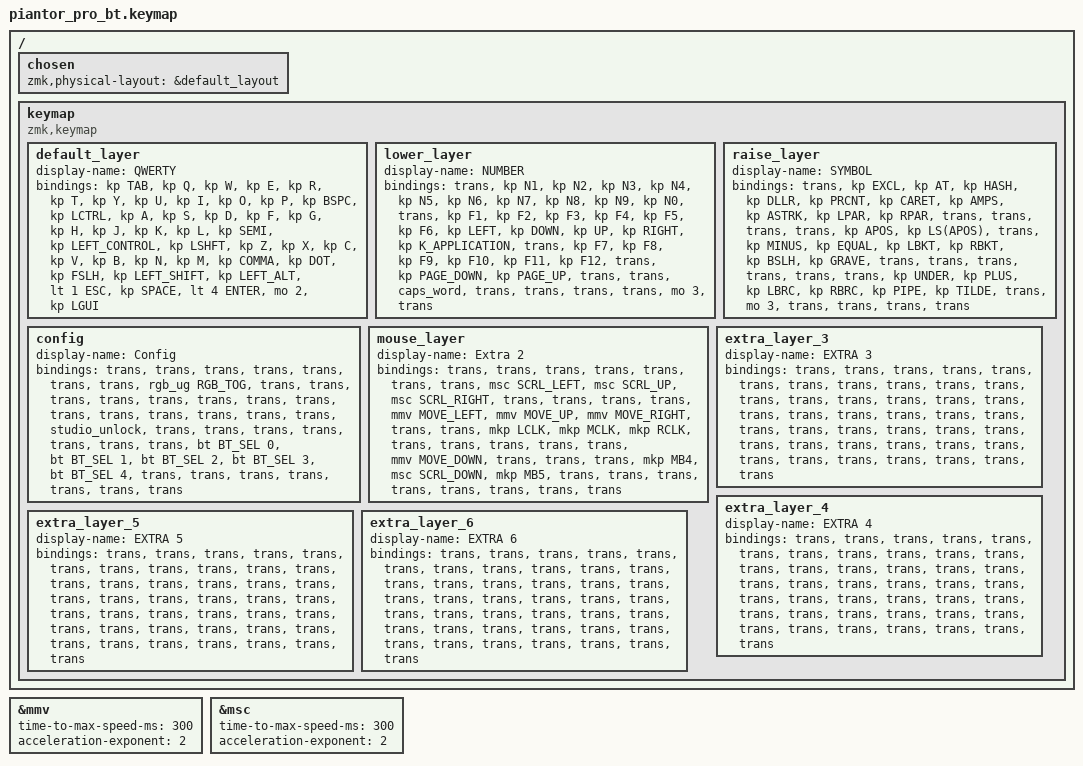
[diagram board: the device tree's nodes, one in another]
/*
 * Copyright (c) 2020 The ZMK Contributors
 *
 * SPDX-License-Identifier: MIT
 */
#define ZMK_POINTING_DEFAULT_MOVE_VAL 1200
#define ZMK_POINTING_DEFAULT_SCRL_VAL 20

#include <behaviors.dtsi>
#include <dt-bindings/zmk/bt.h>
#include <dt-bindings/zmk/keys.h>
#include <dt-bindings/zmk/pointing.h>
#include <dt-bindings/zmk/rgb.h>

&mmv {
    time-to-max-speed-ms = <300>;
    acceleration-exponent = <2>;
};

&msc {
    time-to-max-speed-ms = <300>;
    acceleration-exponent = <2>;
};

/ {
    chosen { zmk,physical-layout = &default_layout; };
};

/ {
    keymap {
        compatible = "zmk,keymap";

        default_layer {
            display-name = "QWERTY";

            // --------------------------------------------------------------------------------
            // |  TAB |  Q  |  W  |  E  |  R  |  T  |  Y  |  U   |  I  |  O  |  P  | BSPC |
            // | CTRL |  A  |  S  |  D  |  F  |  G  |  H  |  J   |  K  |  L  |  ;  |  '   |
            // | SHFT |  Z  |  X  |  C  |  V  |  B  |  N  |  M   |  ,  |  .  |  /  | ESC  |
            //                    | GUI | LWR | SPC | ENT | RSE  | ALT |

            bindings = <
&kp TAB  &kp Q  &kp W  &kp E  &kp R  &kp T  &kp Y  &kp U  &kp I  &kp O  &kp P  &kp BSPC  &kp LCTRL  &kp A  &kp S  &kp D  &kp F  &kp G  &kp H  &kp J  &kp K  &kp L  &kp SEMI  &kp LEFT_CONTROL  &kp LSHFT  &kp Z  &kp X  &kp C  &kp V  &kp B  &kp N  &kp M  &kp COMMA  &kp DOT  &kp FSLH  &kp LEFT_SHIFT  &kp LEFT_ALT  &lt 1 ESC  &kp SPACE  &lt 4 ENTER  &mo 2  &kp LGUI
            >;
        };

        lower_layer {
            display-name = "NUMBER";

            // -----------------------------------------------------------------------------------------
            // |  TAB |  1  |  2  |  3  |  4  |  5    |  6  |  7  |  8  |  9  |  0  | BSPC |
            // | CTRL | BT1 | BT2 | BT3 | BT4 | BT5   | LFT | DWN |  UP | RGT |     |      |
            // | SHFT | BTCR| RGB | RST | BOOT| Unlock|     |     |     |     |     |      |
            //                    | GUI |     | SPC   | ENT |     | ALT |

            bindings = <
&trans  &kp N1  &kp N2  &kp N3  &kp N4  &kp N5  &kp N6  &kp N7  &kp N8  &kp N9  &kp N0  &trans  &kp F1  &kp F2  &kp F3  &kp F4  &kp F5  &kp F6  &kp LEFT  &kp DOWN  &kp UP  &kp RIGHT  &kp K_APPLICATION  &trans  &kp F7  &kp F8  &kp F9  &kp F10  &kp F11  &kp F12  &trans  &kp PAGE_DOWN  &kp PAGE_UP  &trans  &trans  &caps_word  &trans  &trans  &trans  &trans  &mo 3  &trans
            >;
        };

        raise_layer {
            display-name = "SYMBOL";

            // -----------------------------------------------------------------------------------------
            // |  TAB |  !  |  @  |  #  |  $  |  %  |  ^  |  &  |  *  |  (  |  )  | BSPC |
            // | CTRL |     |     |     |     |     |  -  |  =  |  [  |  ]  |  \  |  `   |
            // | SHFT |     |     |     |     |     |  _  |  +  |  {  |  }  | "|" |  ~   |
            //                    | GUI |     | SPC | ENT |     | ALT |

            bindings = <
&trans  &kp EXCL  &kp AT  &kp HASH  &kp DLLR  &kp PRCNT  &kp CARET  &kp AMPS  &kp ASTRK  &kp LPAR  &kp RPAR  &trans  &trans  &trans  &trans  &kp APOS  &kp LS(APOS)  &trans  &kp MINUS  &kp EQUAL  &kp LBKT  &kp RBKT  &kp BSLH  &kp GRAVE  &trans  &trans  &trans  &trans  &trans  &trans  &kp UNDER  &kp PLUS  &kp LBRC  &kp RBRC  &kp PIPE  &kp TILDE  &trans  &mo 3  &trans  &trans  &trans  &trans
            >;
        };

        config {
            display-name = "Config";
            bindings = <
&trans  &trans  &trans  &trans  &trans  &trans  &trans  &rgb_ug RGB_TOG  &trans  &trans  &trans  &trans  &trans  &trans  &trans  &trans  &trans  &trans  &trans  &trans  &trans  &trans  &studio_unlock  &trans  &trans  &trans  &trans  &trans  &trans  &trans  &bt BT_SEL 0  &bt BT_SEL 1  &bt BT_SEL 2  &bt BT_SEL 3  &bt BT_SEL 4  &trans  &trans  &trans  &trans  &trans  &trans  &trans
            >;
        };

        mouse_layer {
            display-name = "Extra 2";
            bindings = <
&trans  &trans  &trans  &trans  &trans  &trans  &trans  &msc SCRL_LEFT  &msc SCRL_UP  &msc SCRL_RIGHT  &trans  &trans  &trans  &trans  &mmv MOVE_LEFT  &mmv MOVE_UP  &mmv MOVE_RIGHT  &trans  &trans  &mkp LCLK  &mkp MCLK  &mkp RCLK  &trans  &trans  &trans  &trans  &trans  &mmv MOVE_DOWN  &trans  &trans  &trans  &mkp MB4  &msc SCRL_DOWN  &mkp MB5  &trans  &trans  &trans  &trans  &trans  &trans  &trans  &trans
            >;
        };

        extra_layer_3 {
            display-name = "EXTRA 3";
            bindings = <
&trans  &trans  &trans  &trans  &trans  &trans  &trans  &trans  &trans  &trans  &trans  &trans  &trans  &trans  &trans  &trans  &trans  &trans  &trans  &trans  &trans  &trans  &trans  &trans  &trans  &trans  &trans  &trans  &trans  &trans  &trans  &trans  &trans  &trans  &trans  &trans  &trans  &trans  &trans  &trans  &trans  &trans
            >;
        };

        extra_layer_4 {
            display-name = "EXTRA 4";
            bindings = <
&trans  &trans  &trans  &trans  &trans  &trans  &trans  &trans  &trans  &trans  &trans  &trans  &trans  &trans  &trans  &trans  &trans  &trans  &trans  &trans  &trans  &trans  &trans  &trans  &trans  &trans  &trans  &trans  &trans  &trans  &trans  &trans  &trans  &trans  &trans  &trans  &trans  &trans  &trans  &trans  &trans  &trans
            >;
        };

        extra_layer_5 {
            display-name = "EXTRA 5";
            bindings = <
&trans  &trans  &trans  &trans  &trans  &trans  &trans  &trans  &trans  &trans  &trans  &trans  &trans  &trans  &trans  &trans  &trans  &trans  &trans  &trans  &trans  &trans  &trans  &trans  &trans  &trans  &trans  &trans  &trans  &trans  &trans  &trans  &trans  &trans  &trans  &trans  &trans  &trans  &trans  &trans  &trans  &trans
            >;
        };

        extra_layer_6 {
            display-name = "EXTRA 6";
            bindings = <
&trans  &trans  &trans  &trans  &trans  &trans  &trans  &trans  &trans  &trans  &trans  &trans  &trans  &trans  &trans  &trans  &trans  &trans  &trans  &trans  &trans  &trans  &trans  &trans  &trans  &trans  &trans  &trans  &trans  &trans  &trans  &trans  &trans  &trans  &trans  &trans  &trans  &trans  &trans  &trans  &trans  &trans
            >;
        };
    };
};
